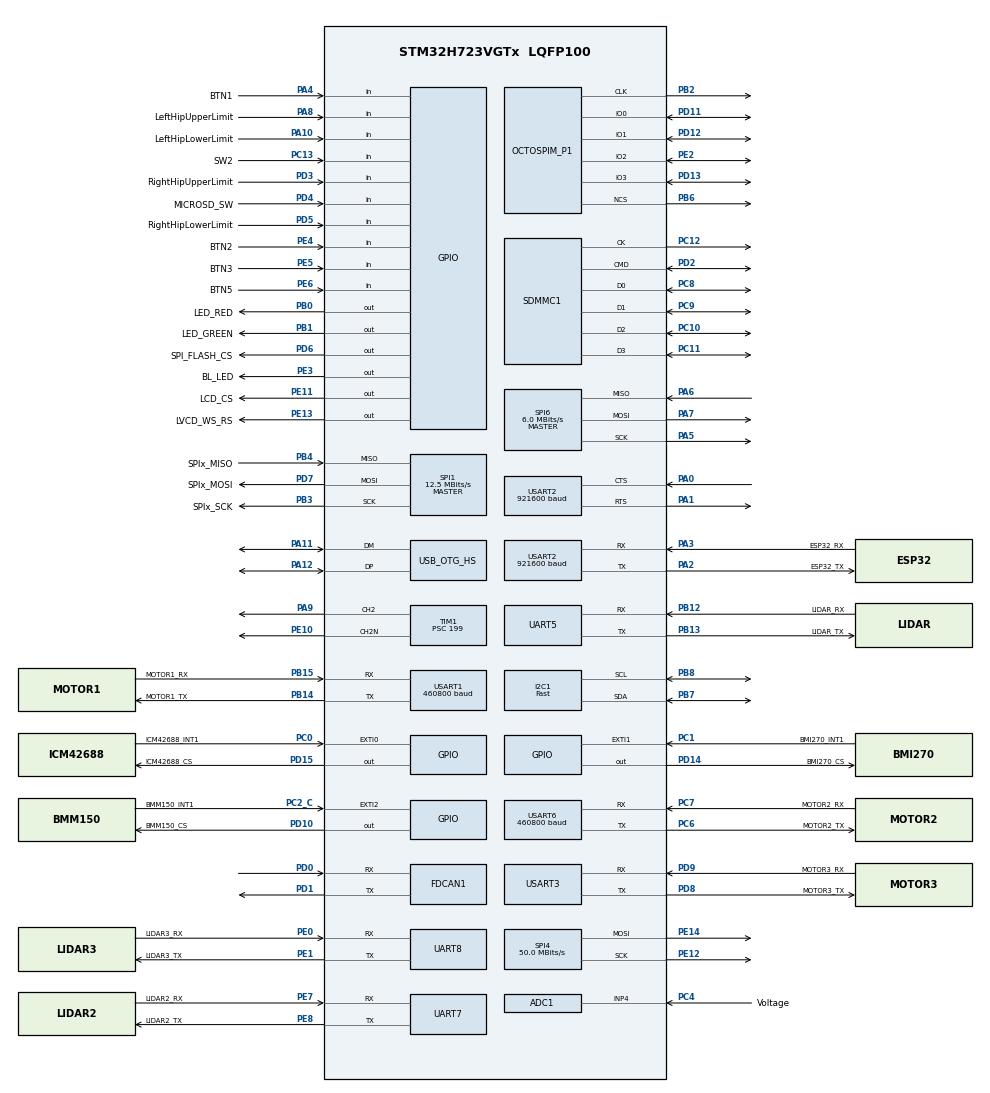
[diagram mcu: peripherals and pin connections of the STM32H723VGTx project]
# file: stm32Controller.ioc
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ADC1.Channel-0\#ChannelRegularConversion=ADC_CHANNEL_4
ADC1.NbrOfConversionFlag=1
ADC1.OffsetNumber-0\#ChannelRegularConversion=ADC_OFFSET_NONE
ADC1.OffsetSignedSaturation-0\#ChannelRegularConversion=DISABLE
ADC1.OversamplingMode=ENABLE
ADC1.Rank-0\#ChannelRegularConversion=1
ADC1.Ratio=16
ADC1.SamplingTime-0\#ChannelRegularConversion=ADC_SAMPLETIME_810CYCLES_5
ADC1.master=1
Bdma.Request0=SPI6_RX
Bdma.Request1=SPI6_TX
Bdma.RequestsNb=2
Bdma.SPI6_RX.0.Direction=DMA_PERIPH_TO_MEMORY
Bdma.SPI6_RX.0.EventEnable=DISABLE
Bdma.SPI6_RX.0.Instance=BDMA_Channel0
Bdma.SPI6_RX.0.MemDataAlignment=DMA_MDATAALIGN_BYTE
Bdma.SPI6_RX.0.MemInc=DMA_MINC_ENABLE
Bdma.SPI6_RX.0.Mode=DMA_NORMAL
Bdma.SPI6_RX.0.PeriphDataAlignment=DMA_PDATAALIGN_BYTE
Bdma.SPI6_RX.0.PeriphInc=DMA_PINC_DISABLE
Bdma.SPI6_RX.0.Polarity=HAL_DMAMUX_REQ_GEN_RISING
Bdma.SPI6_RX.0.Priority=DMA_PRIORITY_HIGH
Bdma.SPI6_RX.0.RequestNumber=1
Bdma.SPI6_RX.0.SignalID=NONE
Bdma.SPI6_RX.0.SyncEnable=DISABLE
Bdma.SPI6_RX.0.SyncPolarity=HAL_DMAMUX_SYNC_NO_EVENT
Bdma.SPI6_RX.0.SyncRequestNumber=1
Bdma.SPI6_RX.0.SyncSignalID=NONE
Bdma.SPI6_TX.1.Direction=DMA_MEMORY_TO_PERIPH
Bdma.SPI6_TX.1.EventEnable=DISABLE
Bdma.SPI6_TX.1.Instance=BDMA_Channel1
Bdma.SPI6_TX.1.MemDataAlignment=DMA_MDATAALIGN_BYTE
Bdma.SPI6_TX.1.MemInc=DMA_MINC_ENABLE
Bdma.SPI6_TX.1.Mode=DMA_NORMAL
Bdma.SPI6_TX.1.PeriphDataAlignment=DMA_PDATAALIGN_BYTE
Bdma.SPI6_TX.1.PeriphInc=DMA_PINC_DISABLE
Bdma.SPI6_TX.1.Polarity=HAL_DMAMUX_REQ_GEN_RISING
Bdma.SPI6_TX.1.Priority=DMA_PRIORITY_HIGH
Bdma.SPI6_TX.1.RequestNumber=1
Bdma.SPI6_TX.1.SignalID=NONE
Bdma.SPI6_TX.1.SyncEnable=DISABLE
Bdma.SPI6_TX.1.SyncPolarity=HAL_DMAMUX_SYNC_NO_EVENT
Bdma.SPI6_TX.1.SyncRequestNumber=1
Bdma.SPI6_TX.1.SyncSignalID=NONE
CORTEX_M7.CPU_DCache=Enabled
CORTEX_M7.CPU_ICache=Enabled
CORTEX_M7.default_mode_Activation=1
Dma.Request0=USART2_RX
Dma.Request1=USART2_TX
Dma.Request2=USART1_RX
Dma.Request3=USART1_TX
Dma.Request4=USART6_RX
Dma.Request5=USART6_TX
Dma.Request6=UART5_RX
Dma.Request7=UART7_RX
Dma.Request8=USART3_RX
Dma.Request9=USART3_TX
Dma.UART5_RX.6.Direction=DMA_PERIPH_TO_MEMORY
Dma.UART5_RX.6.EventEnable=DISABLE
Dma.UART5_RX.6.FIFOMode=DMA_FIFOMODE_DISABLE
Dma.UART5_RX.6.Instance=DMA2_Stream2
Dma.UART5_RX.6.MemDataAlignment=DMA_MDATAALIGN_BYTE
Dma.UART5_RX.6.MemInc=DMA_MINC_ENABLE
Dma.UART5_RX.6.Mode=DMA_CIRCULAR
Dma.UART5_RX.6.PeriphDataAlignment=DMA_PDATAALIGN_BYTE
Dma.UART5_RX.6.PeriphInc=DMA_PINC_DISABLE
Dma.UART5_RX.6.Polarity=HAL_DMAMUX_REQ_GEN_RISING
Dma.UART5_RX.6.Priority=DMA_PRIORITY_MEDIUM
Dma.UART5_RX.6.RequestNumber=1
Dma.UART5_RX.6.SignalID=NONE
Dma.UART5_RX.6.SyncEnable=DISABLE
Dma.UART5_RX.6.SyncPolarity=HAL_DMAMUX_SYNC_NO_EVENT
Dma.UART5_RX.6.SyncRequestNumber=1
Dma.UART5_RX.6.SyncSignalID=NONE
Dma.UART7_RX.7.Direction=DMA_PERIPH_TO_MEMORY
Dma.UART7_RX.7.EventEnable=DISABLE
Dma.UART7_RX.7.FIFOMode=DMA_FIFOMODE_DISABLE
Dma.UART7_RX.7.Instance=DMA2_Stream3
Dma.UART7_RX.7.MemDataAlignment=DMA_MDATAALIGN_BYTE
Dma.UART7_RX.7.MemInc=DMA_MINC_ENABLE
Dma.UART7_RX.7.Mode=DMA_CIRCULAR
Dma.UART7_RX.7.PeriphDataAlignment=DMA_PDATAALIGN_BYTE
Dma.UART7_RX.7.PeriphInc=DMA_PINC_DISABLE
Dma.UART7_RX.7.Polarity=HAL_DMAMUX_REQ_GEN_RISING
Dma.UART7_RX.7.Priority=DMA_PRIORITY_MEDIUM
Dma.UART7_RX.7.RequestNumber=1
Dma.UART7_RX.7.SignalID=NONE
Dma.UART7_RX.7.SyncEnable=DISABLE
Dma.UART7_RX.7.SyncPolarity=HAL_DMAMUX_SYNC_NO_EVENT
Dma.UART7_RX.7.SyncRequestNumber=1
Dma.UART7_RX.7.SyncSignalID=NONE
Dma.USART1_RX.2.Direction=DMA_PERIPH_TO_MEMORY
Dma.USART1_RX.2.EventEnable=DISABLE
Dma.USART1_RX.2.FIFOMode=DMA_FIFOMODE_DISABLE
Dma.USART1_RX.2.Instance=DMA1_Stream6
Dma.USART1_RX.2.MemDataAlignment=DMA_MDATAALIGN_BYTE
Dma.USART1_RX.2.MemInc=DMA_MINC_ENABLE
Dma.USART1_RX.2.Mode=DMA_CIRCULAR
Dma.USART1_RX.2.PeriphDataAlignment=DMA_PDATAALIGN_BYTE
Dma.USART1_RX.2.PeriphInc=DMA_PINC_DISABLE
Dma.USART1_RX.2.Polarity=HAL_DMAMUX_REQ_GEN_RISING
Dma.USART1_RX.2.Priority=DMA_PRIORITY_MEDIUM
Dma.USART1_RX.2.RequestNumber=1
Dma.USART1_RX.2.SignalID=NONE
Dma.USART1_RX.2.SyncEnable=DISABLE
Dma.USART1_RX.2.SyncPolarity=HAL_DMAMUX_SYNC_NO_EVENT
Dma.USART1_RX.2.SyncRequestNumber=1
Dma.USART1_RX.2.SyncSignalID=NONE
Dma.USART1_TX.3.Direction=DMA_MEMORY_TO_PERIPH
Dma.USART1_TX.3.EventEnable=DISABLE
Dma.USART1_TX.3.FIFOMode=DMA_FIFOMODE_DISABLE
Dma.USART1_TX.3.Instance=DMA1_Stream7
Dma.USART1_TX.3.MemDataAlignment=DMA_MDATAALIGN_BYTE
Dma.USART1_TX.3.MemInc=DMA_MINC_ENABLE
Dma.USART1_TX.3.Mode=DMA_NORMAL
Dma.USART1_TX.3.PeriphDataAlignment=DMA_PDATAALIGN_BYTE
Dma.USART1_TX.3.PeriphInc=DMA_PINC_DISABLE
Dma.USART1_TX.3.Polarity=HAL_DMAMUX_REQ_GEN_RISING
Dma.USART1_TX.3.Priority=DMA_PRIORITY_MEDIUM
Dma.USART1_TX.3.RequestNumber=1
Dma.USART1_TX.3.SignalID=NONE
Dma.USART1_TX.3.SyncEnable=DISABLE
Dma.USART1_TX.3.SyncPolarity=HAL_DMAMUX_SYNC_NO_EVENT
Dma.USART1_TX.3.SyncRequestNumber=1
Dma.USART1_TX.3.SyncSignalID=NONE
Dma.USART2_RX.0.Direction=DMA_PERIPH_TO_MEMORY
Dma.USART2_RX.0.EventEnable=DISABLE
Dma.USART2_RX.0.FIFOMode=DMA_FIFOMODE_DISABLE
Dma.USART2_RX.0.Instance=DMA1_Stream4
Dma.USART2_RX.0.MemDataAlignment=DMA_MDATAALIGN_BYTE
Dma.USART2_RX.0.MemInc=DMA_MINC_ENABLE
Dma.USART2_RX.0.Mode=DMA_CIRCULAR
Dma.USART2_RX.0.PeriphDataAlignment=DMA_PDATAALIGN_BYTE
Dma.USART2_RX.0.PeriphInc=DMA_PINC_DISABLE
Dma.USART2_RX.0.Polarity=HAL_DMAMUX_REQ_GEN_RISING
Dma.USART2_RX.0.Priority=DMA_PRIORITY_HIGH
Dma.USART2_RX.0.RequestNumber=1
Dma.USART2_RX.0.SignalID=NONE
Dma.USART2_RX.0.SyncEnable=DISABLE
Dma.USART2_RX.0.SyncPolarity=HAL_DMAMUX_SYNC_NO_EVENT
Dma.USART2_RX.0.SyncRequestNumber=1
Dma.USART2_RX.0.SyncSignalID=NONE
Dma.USART2_TX.1.Direction=DMA_MEMORY_TO_PERIPH
Dma.USART2_TX.1.EventEnable=DISABLE
Dma.USART2_TX.1.FIFOMode=DMA_FIFOMODE_DISABLE
Dma.USART2_TX.1.Instance=DMA1_Stream5
Dma.USART2_TX.1.MemDataAlignment=DMA_MDATAALIGN_BYTE
Dma.USART2_TX.1.MemInc=DMA_MINC_ENABLE
Dma.USART2_TX.1.Mode=DMA_NORMAL
Dma.USART2_TX.1.PeriphDataAlignment=DMA_PDATAALIGN_BYTE
Dma.USART2_TX.1.PeriphInc=DMA_PINC_DISABLE
Dma.USART2_TX.1.Polarity=HAL_DMAMUX_REQ_GEN_RISING
Dma.USART2_TX.1.Priority=DMA_PRIORITY_MEDIUM
Dma.USART2_TX.1.RequestNumber=1
Dma.USART2_TX.1.SignalID=NONE
Dma.USART2_TX.1.SyncEnable=DISABLE
Dma.USART2_TX.1.SyncPolarity=HAL_DMAMUX_SYNC_NO_EVENT
Dma.USART2_TX.1.SyncRequestNumber=1
Dma.USART2_TX.1.SyncSignalID=NONE
Dma.USART3_RX.8.Direction=DMA_PERIPH_TO_MEMORY
Dma.USART3_RX.8.EventEnable=DISABLE
Dma.USART3_RX.8.FIFOMode=DMA_FIFOMODE_DISABLE
Dma.USART3_RX.8.Instance=DMA2_Stream4
Dma.USART3_RX.8.MemDataAlignment=DMA_MDATAALIGN_BYTE
Dma.USART3_RX.8.MemInc=DMA_MINC_ENABLE
Dma.USART3_RX.8.Mode=DMA_CIRCULAR
Dma.USART3_RX.8.PeriphDataAlignment=DMA_PDATAALIGN_BYTE
Dma.USART3_RX.8.PeriphInc=DMA_PINC_DISABLE
Dma.USART3_RX.8.Polarity=HAL_DMAMUX_REQ_GEN_RISING
Dma.USART3_RX.8.Priority=DMA_PRIORITY_MEDIUM
Dma.USART3_RX.8.RequestNumber=1
Dma.USART3_RX.8.SignalID=NONE
Dma.USART3_RX.8.SyncEnable=DISABLE
Dma.USART3_RX.8.SyncPolarity=HAL_DMAMUX_SYNC_NO_EVENT
Dma.USART3_RX.8.SyncRequestNumber=1
Dma.USART3_RX.8.SyncSignalID=NONE
Dma.USART3_TX.9.Direction=DMA_MEMORY_TO_PERIPH
Dma.USART3_TX.9.EventEnable=DISABLE
Dma.USART3_TX.9.FIFOMode=DMA_FIFOMODE_DISABLE
Dma.USART3_TX.9.Instance=DMA2_Stream5
Dma.USART3_TX.9.MemDataAlignment=DMA_MDATAALIGN_BYTE
Dma.USART3_TX.9.MemInc=DMA_MINC_ENABLE
Dma.USART3_TX.9.Mode=DMA_NORMAL
Dma.USART3_TX.9.PeriphDataAlignment=DMA_PDATAALIGN_BYTE
Dma.USART3_TX.9.PeriphInc=DMA_PINC_DISABLE
Dma.USART3_TX.9.Polarity=HAL_DMAMUX_REQ_GEN_RISING
Dma.USART3_TX.9.Priority=DMA_PRIORITY_MEDIUM
Dma.USART3_TX.9.RequestNumber=1
Dma.USART3_TX.9.SignalID=NONE
Dma.USART3_TX.9.SyncEnable=DISABLE
Dma.USART3_TX.9.SyncPolarity=HAL_DMAMUX_SYNC_NO_EVENT
Dma.USART3_TX.9.SyncRequestNumber=1
Dma.USART3_TX.9.SyncSignalID=NONE
Dma.USART6_RX.4.Direction=DMA_PERIPH_TO_MEMORY
Dma.USART6_RX.4.EventEnable=DISABLE
Dma.USART6_RX.4.FIFOMode=DMA_FIFOMODE_DISABLE
Dma.USART6_RX.4.Instance=DMA2_Stream0
Dma.USART6_RX.4.MemDataAlignment=DMA_MDATAALIGN_BYTE
Dma.USART6_RX.4.MemInc=DMA_MINC_ENABLE
Dma.USART6_RX.4.Mode=DMA_CIRCULAR
Dma.USART6_RX.4.PeriphDataAlignment=DMA_PDATAALIGN_BYTE
Dma.USART6_RX.4.PeriphInc=DMA_PINC_DISABLE
Dma.USART6_RX.4.Polarity=HAL_DMAMUX_REQ_GEN_RISING
Dma.USART6_RX.4.Priority=DMA_PRIORITY_MEDIUM
Dma.USART6_RX.4.RequestNumber=1
Dma.USART6_RX.4.SignalID=NONE
Dma.USART6_RX.4.SyncEnable=DISABLE
Dma.USART6_RX.4.SyncPolarity=HAL_DMAMUX_SYNC_NO_EVENT
Dma.USART6_RX.4.SyncRequestNumber=1
Dma.USART6_RX.4.SyncSignalID=NONE
Dma.USART6_TX.5.Direction=DMA_MEMORY_TO_PERIPH
Dma.USART6_TX.5.EventEnable=DISABLE
Dma.USART6_TX.5.FIFOMode=DMA_FIFOMODE_DISABLE
Dma.USART6_TX.5.Instance=DMA2_Stream1
Dma.USART6_TX.5.MemDataAlignment=DMA_MDATAALIGN_BYTE
Dma.USART6_TX.5.MemInc=DMA_MINC_ENABLE
Dma.USART6_TX.5.Mode=DMA_NORMAL
Dma.USART6_TX.5.PeriphDataAlignment=DMA_PDATAALIGN_BYTE
Dma.USART6_TX.5.PeriphInc=DMA_PINC_DISABLE
Dma.USART6_TX.5.Polarity=HAL_DMAMUX_REQ_GEN_RISING
Dma.USART6_TX.5.Priority=DMA_PRIORITY_MEDIUM
Dma.USART6_TX.5.RequestNumber=1
Dma.USART6_TX.5.SignalID=NONE
Dma.USART6_TX.5.SyncEnable=DISABLE
Dma.USART6_TX.5.SyncPolarity=HAL_DMAMUX_SYNC_NO_EVENT
Dma.USART6_TX.5.SyncRequestNumber=1
Dma.USART6_TX.5.SyncSignalID=NONE
FATFS.BSP.number=1
FATFS.USE_DMA_CODE_SD=1
FATFS._FS_EXFAT=1
FATFS._USE_LFN=1
FATFS0.BSP.STBoard=false
FATFS0.BSP.api=Unknown
FATFS0.BSP.instance=PD4
FATFS0.BSP.ip=GPIO
FATFS0.BSP.mode=Input
FATFS0.BSP.name=Detect_SDIO
FATFS0.BSP.solution=PD4
FDCAN1.AutoRetransmission=ENABLE
FDCAN1.CalculateBaudRateNominal=500000
FDCAN1.CalculateTimeBitNominal=2000
FDCAN1.CalculateTimeQuantumNominal=100.0
FDCAN1.NominalPrescaler=10
FDCAN1.NominalTimeSeg1=15
FDCAN1.NominalTimeSeg2=4
FDCAN1.RxFifo0ElmtsNbr=8
FDCAN1.StdFiltersNbr=4
FDCAN1.TxBuffersNbr=16
FDCAN1.TxFifoQueueElmtsNbr=16
I2C1.I2C_Speed_Mode=I2C_Fast
I2C1.Timing=0x009034B6
IWDG1.Prescaler=IWDG_PRESCALER_256
IWDG1.Reload=500
IWDG1.Window=500
Mcu.Family=STM32H7
Mcu.Name=STM32H723VGTx
Mcu.Package=LQFP100
Mdma.MDMA_Channel0.OCTOSPI1_FIFO_TH.0.BlockCount=1
Mdma.MDMA_Channel0.OCTOSPI1_FIFO_TH.0.BlockDataLength=1
Mdma.MDMA_Channel0.OCTOSPI1_FIFO_TH.0.BufferTransferLength=16
Mdma.MDMA_Channel0.OCTOSPI1_FIFO_TH.0.CircularMode=MDMA_LINEAR_LIST
Mdma.MDMA_Channel0.OCTOSPI1_FIFO_TH.0.DataAlignment=MDMA_DATAALIGN_PACKENABLE
Mdma.MDMA_Channel0.OCTOSPI1_FIFO_TH.0.DestBlockAddressOffset=0
Mdma.MDMA_Channel0.OCTOSPI1_FIFO_TH.0.DestBurst=MDMA_DEST_BURST_SINGLE
Mdma.MDMA_Channel0.OCTOSPI1_FIFO_TH.0.DestDataSize=MDMA_DEST_DATASIZE_WORD
Mdma.MDMA_Channel0.OCTOSPI1_FIFO_TH.0.DestinationInc=MDMA_DEST_INC_DISABLE
Mdma.MDMA_Channel0.OCTOSPI1_FIFO_TH.0.DstAddress=0
Mdma.MDMA_Channel0.OCTOSPI1_FIFO_TH.0.Endianness=MDMA_LITTLE_ENDIANNESS_PRESERVE
Mdma.MDMA_Channel0.OCTOSPI1_FIFO_TH.0.Instance=MDMA_Channel0
Mdma.MDMA_Channel0.OCTOSPI1_FIFO_TH.0.MaskAddress=0
Mdma.MDMA_Channel0.OCTOSPI1_FIFO_TH.0.MaskData=0
Mdma.MDMA_Channel0.OCTOSPI1_FIFO_TH.0.Priority=MDMA_PRIORITY_LOW
Mdma.MDMA_Channel0.OCTOSPI1_FIFO_TH.0.Rank=First
Mdma.MDMA_Channel0.OCTOSPI1_FIFO_TH.0.SourceBlockAddressOffset=0
Mdma.MDMA_Channel0.OCTOSPI1_FIFO_TH.0.SourceBurst=MDMA_SOURCE_BURST_SINGLE
Mdma.MDMA_Channel0.OCTOSPI1_FIFO_TH.0.SourceDataSize=MDMA_SRC_DATASIZE_BYTE
Mdma.MDMA_Channel0.OCTOSPI1_FIFO_TH.0.SourceInc=MDMA_SRC_INC_BYTE
Mdma.MDMA_Channel0.OCTOSPI1_FIFO_TH.0.SrcAddress=0
Mdma.MDMA_Channel0.OCTOSPI1_FIFO_TH.0.TransferTriggerMode=MDMA_BUFFER_TRANSFER
Mdma.MDMA_Channel0.Request0=OCTOSPI1_FIFO_TH
Mdma.MDMA_Channel0.RequestsNb=1
Mdma.RequestSet0=MDMA_Channel0
Mdma.RequestSetsNb=1
NVIC.BDMA_Channel0_IRQn=true\:0\:0\:false\:false\:true\:false\:true\:true
NVIC.BDMA_Channel1_IRQn=true\:0\:0\:false\:false\:true\:false\:true\:true
NVIC.DMA1_Stream4_IRQn=true\:0\:0\:false\:false\:true\:false\:true\:true
NVIC.DMA1_Stream5_IRQn=true\:0\:0\:false\:false\:true\:false\:true\:true
NVIC.DMA1_Stream6_IRQn=true\:0\:0\:false\:false\:true\:false\:true\:true
NVIC.DMA1_Stream7_IRQn=true\:0\:0\:false\:false\:true\:false\:true\:true
NVIC.DMA2_Stream0_IRQn=true\:0\:0\:false\:false\:true\:false\:true\:true
NVIC.DMA2_Stream1_IRQn=true\:0\:0\:false\:false\:true\:false\:true\:true
NVIC.DMA2_Stream2_IRQn=true\:0\:0\:false\:false\:true\:false\:true\:true
NVIC.DMA2_Stream3_IRQn=true\:0\:0\:false\:false\:true\:false\:true\:true
NVIC.DMA2_Stream4_IRQn=true\:0\:0\:false\:false\:true\:false\:true\:true
NVIC.DMA2_Stream5_IRQn=true\:0\:0\:false\:false\:true\:false\:true\:true
NVIC.EXTI0_IRQn=true\:0\:0\:false\:false\:true\:true\:true\:true
NVIC.EXTI1_IRQn=true\:0\:0\:false\:false\:true\:true\:true\:true
NVIC.EXTI2_IRQn=true\:0\:0\:false\:false\:true\:true\:true\:true
NVIC.FDCAN1_IT0_IRQn=true\:0\:0\:false\:false\:true\:true\:true\:true
NVIC.I2C1_ER_IRQn=true\:0\:0\:false\:false\:true\:true\:true\:true
NVIC.I2C1_EV_IRQn=true\:0\:0\:false\:false\:true\:true\:true\:true
NVIC.MDMA_IRQn=true\:0\:0\:false\:false\:true\:false\:true\:true
NVIC.OCTOSPI1_IRQn=true\:0\:0\:false\:false\:true\:true\:true\:true
NVIC.OTG_HS_IRQn=true\:0\:0\:false\:false\:true\:false\:true\:true
NVIC.PriorityGroup=NVIC_PRIORITYGROUP_4
NVIC.SDMMC1_IRQn=true\:6\:0\:true\:false\:true\:true\:true\:true
NVIC.SPI6_IRQn=true\:0\:0\:false\:false\:true\:false\:true\:true
NVIC.TIM2_IRQn=true\:5\:0\:true\:false\:true\:true\:true\:true
NVIC.USART1_IRQn=true\:0\:0\:false\:false\:true\:true\:true\:true
NVIC.USART2_IRQn=true\:0\:0\:false\:false\:true\:true\:true\:true
NVIC.USART3_IRQn=true\:0\:0\:false\:false\:true\:true\:true\:true
NVIC.USART6_IRQn=true\:0\:0\:false\:false\:true\:true\:true\:true
OCTOSPI1.ChipSelectHighTime=2
OCTOSPI1.ClockMode=HAL_OSPI_CLOCK_MODE_3
OCTOSPI1.ClockPrescaler=3-1
OCTOSPI1.DeviceSize=23
OCTOSPI1.FifoThreshold=16
OCTOSPI1.MemoryType=HAL_OSPI_MEMTYPE_MICRON
OCTOSPI1.SampleShifting=HAL_OSPI_SAMPLE_SHIFTING_HALFCYCLE
PA0.Mode=CTS_RTS
PA0.Signal=USART2_CTS
PA1.Mode=CTS_RTS
PA1.Signal=USART2_RTS
PA10.GPIO_Label=LeftHipLowerLimit
PA10.GPIO_PuPd=GPIO_PULLUP
PA10.Signal=GPIO_Input
PA11.Mode=Device_Only_FS
PA11.Signal=USB_OTG_HS_DM
PA12.Mode=Device_Only_FS
PA12.Signal=USB_OTG_HS_DP
PA13(JTMS/SWDIO).Mode=Serial_Wire
PA13(JTMS/SWDIO).Signal=DEBUG_JTMS-SWDIO
PA14(JTCK/SWCLK).Mode=Serial_Wire
PA14(JTCK/SWCLK).Signal=DEBUG_JTCK-SWCLK
PA2.GPIO_Label=ESP32_TX
PA2.Mode=Asynchronous
PA2.Signal=USART2_TX
PA3.GPIO_Label=ESP32_RX
PA3.Mode=Asynchronous
PA3.Signal=USART2_RX
PA4.GPIO_Label=BTN1
PA4.Signal=GPIO_Input
PA5.GPIO_Mode=GPIO_MODE_AF_PP
PA5.GPIO_Speed=GPIO_SPEED_FREQ_VERY_HIGH
PA5.Mode=Full_Duplex_Master
PA5.Signal=SPI6_SCK
PA6.GPIO_Speed=GPIO_SPEED_FREQ_VERY_HIGH
PA6.Mode=Full_Duplex_Master
PA6.Signal=SPI6_MISO
PA7.GPIO_Speed=GPIO_SPEED_FREQ_VERY_HIGH
PA7.Mode=Full_Duplex_Master
PA7.Signal=SPI6_MOSI
PA8.GPIO_Label=LeftHipUpperLimit
PA8.GPIO_PuPd=GPIO_PULLUP
PA8.Signal=GPIO_Input
PA9.Signal=S_TIM1_CH2
PB0.GPIO_Label=LED_RED
PB0.Signal=GPIO_Output
PB1.GPIO_Label=LED_GREEN
PB1.Signal=GPIO_Output
PB12.GPIO_Label=LIDAR_RX
PB12.Mode=Asynchronous
PB12.Signal=UART5_RX
PB13.GPIO_Label=LIDAR_TX
PB13.Mode=Asynchronous
PB13.Signal=UART5_TX
PB14.GPIO_Label=MOTOR1_TX
PB14.Mode=Asynchronous
PB14.Signal=USART1_TX
PB15.GPIO_Label=MOTOR1_RX
PB15.Mode=Asynchronous
PB15.Signal=USART1_RX
PB2.Mode=O1_P1_CLK
PB2.Signal=OCTOSPIM_P1_CLK
PB3(JTDO/TRACESWO).GPIO_Label=SPIx_SCK
PB3(JTDO/TRACESWO).Mode=Full_Duplex_Master
PB3(JTDO/TRACESWO).Signal=SPI1_SCK
PB4(NJTRST).GPIO_Label=SPIx_MISO
PB4(NJTRST).Mode=Full_Duplex_Master
PB4(NJTRST).Signal=SPI1_MISO
PB6.Mode=OCTOSPI1_Port1_NCS
PB6.Signal=OCTOSPIM_P1_NCS
PB7.Mode=I2C
PB7.Signal=I2C1_SDA
PB8.Mode=I2C
PB8.Signal=I2C1_SCL
PC0.GPIO_Label=ICM42688_INT1
PC0.GPIO_ModeDefaultEXTI=GPIO_MODE_IT_RISING
PC0.Signal=GPXTI0
PC1.GPIO_Label=BMI270_INT1
PC1.Signal=GPXTI1
PC10.Mode=SD_4_bits_Wide_bus
PC10.Signal=SDMMC1_D2
PC11.Mode=SD_4_bits_Wide_bus
PC11.Signal=SDMMC1_D3
PC12.Mode=SD_4_bits_Wide_bus
PC12.Signal=SDMMC1_CK
PC13.GPIO_Label=SW2
PC13.Signal=GPIO_Input
PC2_C.GPIO_Label=BMM150_INT1
PC2_C.Signal=GPXTI2
PC4.GPIO_Label=Voltage
PC4.Signal=ADCx_INP4
PC6.GPIO_Label=MOTOR2_TX
PC6.Mode=Asynchronous
PC6.Signal=USART6_TX
PC7.GPIO_Label=MOTOR2_RX
PC7.Mode=Asynchronous
PC7.Signal=USART6_RX
PC8.Mode=SD_4_bits_Wide_bus
PC8.Signal=SDMMC1_D0
PC9.Mode=SD_4_bits_Wide_bus
PC9.Signal=SDMMC1_D1
PD0.GPIO_Speed=GPIO_SPEED_FREQ_VERY_HIGH
PD0.Mode=FDCAN_Activate
PD0.Signal=FDCAN1_RX
PD1.GPIO_Speed=GPIO_SPEED_FREQ_VERY_HIGH
PD1.Mode=FDCAN_Activate
PD1.Signal=FDCAN1_TX
PD10.GPIO_Label=BMM150_CS
PD10.GPIO_Speed=GPIO_SPEED_FREQ_VERY_HIGH
PD10.PinState=GPIO_PIN_SET
PD10.Signal=GPIO_Output
PD11.Mode=OCTOSPI1_IOL_Port1L
PD11.Signal=OCTOSPIM_P1_IO0
PD12.Mode=OCTOSPI1_IOL_Port1L
PD12.Signal=OCTOSPIM_P1_IO1
PD13.Mode=OCTOSPI1_IOL_Port1L
PD13.Signal=OCTOSPIM_P1_IO3
PD14.GPIO_Label=BMI270_CS
PD14.GPIO_Speed=GPIO_SPEED_FREQ_VERY_HIGH
PD14.PinState=GPIO_PIN_SET
PD14.Signal=GPIO_Output
PD15.GPIO_Label=ICM42688_CS
PD15.GPIO_Speed=GPIO_SPEED_FREQ_VERY_HIGH
PD15.PinState=GPIO_PIN_SET
PD15.Signal=GPIO_Output
PD2.Mode=SD_4_bits_Wide_bus
PD2.Signal=SDMMC1_CMD
PD3.GPIO_Label=RightHipUpperLimit
PD3.GPIO_PuPd=GPIO_PULLUP
PD3.Signal=GPIO_Input
PD4.GPIO_Label=MICROSD_SW
PD4.GPIO_PuPd=GPIO_PULLUP
PD4.Signal=GPIO_Input
PD5.GPIO_Label=RightHipLowerLimit
PD5.GPIO_PuPd=GPIO_PULLUP
PD5.Signal=GPIO_Input
PD6.GPIO_Label=SPI_FLASH_CS
PD6.GPIO_Speed=GPIO_SPEED_FREQ_VERY_HIGH
PD6.PinState=GPIO_PIN_SET
PD6.Signal=GPIO_Output
PD7.GPIO_Label=SPIx_MOSI
PD7.Mode=Full_Duplex_Master
PD7.Signal=SPI1_MOSI
PD8.GPIO_Label=MOTOR3_TX
PD8.Mode=Asynchronous
PD8.Signal=USART3_TX
PD9.GPIO_Label=MOTOR3_RX
PD9.Mode=Asynchronous
PD9.Signal=USART3_RX
PE0.GPIO_Label=LIDAR3_RX
PE0.Mode=Asynchronous
PE0.Signal=UART8_RX
PE1.GPIO_Label=LIDAR3_TX
PE1.Mode=Asynchronous
PE1.Signal=UART8_TX
PE10.Mode=PWM Generation2 CH2 CH2N
PE10.Signal=TIM1_CH2N
PE11.GPIO_Label=LCD_CS
PE11.GPIO_Speed=GPIO_SPEED_FREQ_HIGH
PE11.Signal=GPIO_Output
PE12.Mode=TX_Only_Simplex_Unidirect_Master
PE12.Signal=SPI4_SCK
PE13.GPIO_Label=LVCD_WS_RS
PE13.GPIO_Speed=GPIO_SPEED_FREQ_HIGH
PE13.Signal=GPIO_Output
PE14.Mode=TX_Only_Simplex_Unidirect_Master
PE14.Signal=SPI4_MOSI
PE2.Mode=OCTOSPI1_IOL_Port1L
PE2.Signal=OCTOSPIM_P1_IO2
PE3.GPIO_Label=BL_LED
PE3.Signal=GPIO_Output
PE4.GPIO_Label=BTN2
PE4.GPIO_PuPd=GPIO_PULLUP
PE4.Signal=GPIO_Input
PE5.GPIO_Label=BTN3
PE5.GPIO_PuPd=GPIO_PULLUP
PE5.Signal=GPIO_Input
PE6.GPIO_Label=BTN5
PE6.GPIO_PuPd=GPIO_PULLUP
PE6.Signal=GPIO_Input
PE7.GPIO_Label=LIDAR2_RX
PE7.Mode=Asynchronous
PE7.Signal=UART7_RX
PE8.GPIO_Label=LIDAR2_TX
PE8.Mode=Asynchronous
PE8.Signal=UART7_TX
PH0-OSC_IN.Mode=HSE-External-Oscillator
PH0-OSC_IN.Signal=RCC_OSC_IN
PH1-OSC_OUT.Mode=HSE-External-Oscillator
PH1-OSC_OUT.Signal=RCC_OSC_OUT
ProjectManager.HeapSize=0x200
ProjectManager.StackSize=0x400
ProjectManager.TargetToolchain=CMake
RCC.ADCFreq_Value=100000000
RCC.APB1Freq_Value=100000000
RCC.APB2Freq_Value=100000000
RCC.APB3Freq_Value=100000000
RCC.APB4Freq_Value=100000000
RCC.CortexFreq_Value=400000000
RCC.D1PPRE=RCC_APB3_DIV2
RCC.D2PPRE1=RCC_APB1_DIV2
RCC.D2PPRE2=RCC_APB2_DIV2
RCC.D3PPRE=RCC_APB4_DIV2
RCC.DIVM1=5
RCC.DIVM2=5
RCC.DIVM3=5
RCC.DIVN1=160
RCC.DIVN2=80
RCC.DIVN3=96
RCC.DIVP2=4
RCC.DIVQ2=4
RCC.DIVQ3=10
RCC.DIVR2=4
RCC.FDCANCLockSelection=RCC_FDCANCLKSOURCE_PLL2
RCC.HCLKFreq_Value=200000000
RCC.HPRE=RCC_HCLK_DIV2
RCC.HSE_VALUE=25000000
RCC.PLL2FRACN=0
RCC.PLL3FRACN=0
RCC.PLLFRACN=0
RCC.PLLSourceVirtual=RCC_PLLSOURCE_HSE
RCC.QSPICLockSelection=RCC_OSPICLKSOURCE_PLL2
RCC.SDMMC1CLockSelection=RCC_SDMMCCLKSOURCE_PLL2
RCC.SPI123CLockSelection=RCC_SPI123CLKSOURCE_PLL2
RCC.SPI6CLockSelection=RCC_SPI6CLKSOURCE_PLL3
RCC.SYSCLKFreq_VALUE=400000000
RCC.SYSCLKSource=RCC_SYSCLKSOURCE_PLLCLK
RCC.USBCLockSelection=RCC_USBCLKSOURCE_PLL3
RCC.USBFreq_Value=48000000
SDMMC1.ClockDiv=1
SH.ADCx_INP4.0=ADC1_INP4,IN4-Single-Ended
SH.S_TIM1_CH2.0=TIM1_CH2,PWM Generation2 CH2 CH2N
SPI1.BaudRatePrescaler=SPI_BAUDRATEPRESCALER_8
SPI1.CalculateBaudRate=12.5 MBits/s
SPI1.Direction=SPI_DIRECTION_2LINES
SPI1.Mode=SPI_MODE_MASTER
SPI1.VirtualType=VM_MASTER
SPI4.CalculateBaudRate=50.0 MBits/s
SPI4.Direction=SPI_DIRECTION_2LINES_TXONLY
SPI4.Mode=SPI_MODE_MASTER
SPI4.VirtualType=VM_MASTER
SPI6.BaudRatePrescaler=SPI_BAUDRATEPRESCALER_8
SPI6.CLKPolarity=SPI_POLARITY_LOW
SPI6.CalculateBaudRate=6.0 MBits/s
SPI6.DataSize=SPI_DATASIZE_8BIT
SPI6.Direction=SPI_DIRECTION_2LINES
SPI6.Mode=SPI_MODE_MASTER
SPI6.VirtualType=VM_MASTER
TIM1.AutoReloadPreload=TIM_AUTORELOAD_PRELOAD_ENABLE
TIM1.Channel-PWM\ Generation2\ CH2\ CH2N=TIM_CHANNEL_2
TIM1.Period=44
TIM1.Prescaler=199
TIM2.AutoReloadPreload=TIM_AUTORELOAD_PRELOAD_ENABLE
TIM2.Period=999
TIM2.Prescaler=499
USART1.BaudRate=460800
USART1.VirtualMode-Asynchronous=VM_ASYNC
USART2.BaudRate=921600
USART2.VirtualMode-Asynchronous=VM_ASYNC
USART3.VirtualMode-Asynchronous=VM_ASYNC
USART6.BaudRate=460800
USART6.VirtualMode=VM_ASYNC
USB_DEVICE.CLASS_NAME_HS=CDC
USB_DEVICE.VirtualMode=Cdc
USB_DEVICE.VirtualModeHS=Cdc_HS
USB_OTG_HS.VirtualMode-Device_Only_FS=Device_Only_FS
VP_CRC_VS_CRC.Mode=CRC_Activate
VP_FATFS_VS_SDIO.Mode=SDIO
VP_IWDG1_VS_IWDG.Mode=IWDG_Activate
VP_MEMORYMAP_VS_MEMORYMAP.Mode=CurAppReg
VP_OCTOSPI1_VS_quad.Mode=quad_mode
VP_TIM2_VS_ClockSourceINT.Mode=Internal
VP_USB_DEVICE_VS_USB_DEVICE_CDC_HS.Mode=CDC_HS
board=custom

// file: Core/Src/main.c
/* USER CODE BEGIN Header */
/**
 ******************************************************************************
 * @file           : main.c
 * @brief          : Main program body
 ******************************************************************************
 * @attention
 *
 * Copyright (c) 2025 STMicroelectronics.
 * All rights reserved.
 *
 * This software is licensed under terms that can be found in the LICENSE file
 * in the root directory of this software component.
 * If no LICENSE file comes with this software, it is provided AS-IS.
 *
 ******************************************************************************
 */
/* USER CODE END Header */
#include "main.h"
#include "fatfs.h"
#include "usb_device.h"

/* USER CODE BEGIN Includes */
#include "app_main.h"
#include "bsp_driver_sd.h"
#include "debug_wdog.h"
#include "log.h"
#include "app_config.h"
#include "system_reboot.h"
#include "param_storage.h"
/* USER CODE END Includes */

ADC_HandleTypeDef hadc1;

CRC_HandleTypeDef hcrc;

FDCAN_HandleTypeDef hfdcan1;

I2C_HandleTypeDef hi2c1;

IWDG_HandleTypeDef hiwdg1;

OSPI_HandleTypeDef hospi1;
MDMA_HandleTypeDef hmdma_octospi1_fifo_th;

SD_HandleTypeDef hsd1;

SPI_HandleTypeDef hspi1;
SPI_HandleTypeDef hspi4;
SPI_HandleTypeDef hspi6;
DMA_HandleTypeDef hdma_spi6_rx;
DMA_HandleTypeDef hdma_spi6_tx;

TIM_HandleTypeDef htim1;
TIM_HandleTypeDef htim2;

UART_HandleTypeDef huart5;
UART_HandleTypeDef huart7;
UART_HandleTypeDef huart8;
UART_HandleTypeDef huart1;
UART_HandleTypeDef huart2;
UART_HandleTypeDef huart3;
UART_HandleTypeDef huart6;
DMA_HandleTypeDef hdma_uart5_rx;
DMA_HandleTypeDef hdma_uart7_rx;
DMA_HandleTypeDef hdma_usart1_rx;
DMA_HandleTypeDef hdma_usart1_tx;
DMA_HandleTypeDef hdma_usart2_rx;
DMA_HandleTypeDef hdma_usart2_tx;
DMA_HandleTypeDef hdma_usart3_rx;
DMA_HandleTypeDef hdma_usart3_tx;
DMA_HandleTypeDef hdma_usart6_rx;
DMA_HandleTypeDef hdma_usart6_tx;

void SystemClock_Config(void);
void PeriphCommonClock_Config(void);
static void MPU_Config(void);
static void MX_GPIO_Init(void);
static void MX_DMA_Init(void);
static void MX_BDMA_Init(void);
static void MX_MDMA_Init(void);
static void MX_I2C1_Init(void);
static void MX_OCTOSPI1_Init(void);
static void MX_SDMMC1_SD_Init(void);
static void MX_USART2_UART_Init(void);
static void MX_USART1_UART_Init(void);
static void MX_USART6_UART_Init(void);
static void MX_SPI1_Init(void);
static void MX_SPI4_Init(void);
static void MX_TIM1_Init(void);
static void MX_UART5_Init(void);
static void MX_UART7_Init(void);
static void MX_UART8_Init(void);
static void MX_USART3_UART_Init(void);
static void MX_SPI6_Init(void);
static void MX_CRC_Init(void);
static void MX_IWDG1_Init(void);
static void MX_ADC1_Init(void);
static void MX_TIM2_Init(void);
static void MX_FDCAN1_Init(void);

int main(void)
{

  /* MPU Configuration--------------------------------------------------------*/
  MPU_Config();

  /* Enable the CPU Cache */

  /* Enable I-Cache---------------------------------------------------------*/
  SCB_EnableICache();

  /* Enable D-Cache---------------------------------------------------------*/
  SCB_EnableDCache();

  /* MCU Configuration--------------------------------------------------------*/

  /* Reset of all peripherals, Initializes the Flash interface and the Systick. */
  HAL_Init();

  /* USER CODE BEGIN Init */
  /*
   * Initialize debug watchdog early to detect IWDG resets.
   * Must be after HAL_Init() for backup SRAM access.
   * NOTE: WDOG_CHECKPOINT() cannot be called yet - IWDG not initialized.
   */
  debug_wdog_init();
#if DEBUG_FAULTS
  /* Make bus faults precise and trap on bus errors during debug. */
  SCB->SHCSR |= SCB_SHCSR_BUSFAULTENA_Msk;
#if defined(SCnSCB_ACTLR_DISDEFWBUF_Msk)
  SCnSCB->ACTLR |= SCnSCB_ACTLR_DISDEFWBUF_Msk;
#endif
#endif
  /* USER CODE END Init */

  /* Configure the system clock */
  SystemClock_Config();

  /* Configure the peripherals common clocks */
  PeriphCommonClock_Config();

  /* USER CODE BEGIN SysInit */
  /* NOTE: WDOG_CHECKPOINT() cannot be called yet - IWDG not initialized */
  /* USER CODE END SysInit */

  /* Initialize all configured peripherals */
  MX_GPIO_Init();
  MX_DMA_Init();
  MX_BDMA_Init();
  MX_MDMA_Init();
  MX_I2C1_Init();
  MX_OCTOSPI1_Init();
  MX_SDMMC1_SD_Init();
  MX_USB_DEVICE_Init();
  MX_USART2_UART_Init();
  MX_FATFS_Init();
  MX_USART1_UART_Init();
  MX_USART6_UART_Init();
  MX_SPI1_Init();
  MX_SPI4_Init();
  MX_TIM1_Init();
  MX_UART5_Init();
  MX_UART7_Init();
  MX_UART8_Init();
  MX_USART3_UART_Init();
  MX_SPI6_Init();
  MX_CRC_Init();
  MX_IWDG1_Init();
  MX_ADC1_Init();
  MX_TIM2_Init();
  MX_FDCAN1_Init();
  /* USER CODE BEGIN 2 */
  WDOG_CHECKPOINT(WDOG_CP_IWDG_INIT);

  /*
   * Log watchdog reset info if this was a recovery from hang.
   * Note: USB not yet enumerated, so this goes to the ring buffer
   * and will be sent once USB is ready.
   */
  if (debug_wdog_was_reset()) {
    app_log_printf("[WDOG] Reset detected! Last checkpoint: 0x%04X (%s)\r\n",
                   debug_wdog_get_last_checkpoint(),
                   debug_wdog_checkpoint_name(debug_wdog_get_last_checkpoint()));
  }
  debug_wdog_fault_t fault;
  if (debug_wdog_get_fault(&fault)) {
    app_log_printf("[FAULT] hfsr=0x%08lX cfsr=0x%08lX bfar=0x%08lX "
                   "mmfar=0x%08lX lr=0x%08lX pc=0x%08lX psr=0x%08lX sp=0x%08lX\r\n",
                   (unsigned long)fault.hfsr,
                   (unsigned long)fault.cfsr,
                   (unsigned long)fault.bfar,
                   (unsigned long)fault.mmfar,
                   (unsigned long)fault.lr,
                   (unsigned long)fault.pc,
                   (unsigned long)fault.psr,
                   (unsigned long)fault.sp);
    uint8_t fault_in_param = 0U;
    if (fault.bfar >= PARAM_FLASH_BASE && fault.bfar < PARAM_FLASH_END) {
      fault_in_param = 1U;
    }
    if (fault.mmfar >= PARAM_FLASH_BASE && fault.mmfar < PARAM_FLASH_END) {
      fault_in_param = 1U;
    }
    if (fault_in_param != 0U && (fault.cfsr & 0x0000FF00U) != 0U) {
      app_log_printf("[WDOG] Param flash fault; erasing param sector\r\n");
      int erase_rc = param_storage_erase();
      if (erase_rc == PARAM_OK) {
        app_log_printf("[WDOG] Param flash erase OK\r\n");
      } else {
        app_log_printf("[WDOG] Param flash erase FAILED (%d)\r\n", erase_rc);
      }
      app_log_flush_blocking(50U);
    }
  }

  /*
   * EXTI Race Condition Fix:
   * CubeMX enables IMU EXTI interrupts in MX_GPIO_Init(), but IMU sensors
   * are not initialized until app_init(). On cold boot, sensors may be in
   * an undefined state and generate spurious interrupts that corrupt the
   * scheduler state before it's ready.
   *
   * Solution: Disable IMU EXTI immediately after MX_GPIO_Init() completes.
   * They will be re-enabled in app_init() after successful sensor init.
   * See: docs/CodeReview311225.md for full analysis.
   */
  HAL_NVIC_DisableIRQ(ICM42688_INT1_EXTI_IRQn);
  HAL_NVIC_DisableIRQ(BMI270_INT1_EXTI_IRQn);
  HAL_NVIC_DisableIRQ(BMM150_INT1_EXTI_IRQn);
  WDOG_CHECKPOINT(WDOG_CP_EXTI_DISABLE);

  HAL_GPIO_WritePin(LED_GREEN_GPIO_Port, LED_GREEN_Pin, GPIO_PIN_SET);
  WDOG_CHECKPOINT(WDOG_CP_APP_MAIN_ENTER);
  app_main();
  /* USER CODE END 2 */

  /* Infinite loop */
  while (1) {

  }
}

void SystemClock_Config(void)
{
  RCC_OscInitTypeDef RCC_OscInitStruct = {0};
  RCC_ClkInitTypeDef RCC_ClkInitStruct = {0};

  /** Supply configuration update enable
  */
  HAL_PWREx_ConfigSupply(PWR_LDO_SUPPLY);

  /** Configure the main internal regulator output voltage
  */
  __HAL_PWR_VOLTAGESCALING_CONFIG(PWR_REGULATOR_VOLTAGE_SCALE1);

  while(!__HAL_PWR_GET_FLAG(PWR_FLAG_VOSRDY)) {}

  /** Initializes the RCC Oscillators according to the specified parameters
  * in the RCC_OscInitTypeDef structure.
  */
  RCC_OscInitStruct.OscillatorType = RCC_OSCILLATORTYPE_LSI|RCC_OSCILLATORTYPE_HSE;
  RCC_OscInitStruct.HSEState = RCC_HSE_ON;
  RCC_OscInitStruct.LSIState = RCC_LSI_ON;
  RCC_OscInitStruct.PLL.PLLState = RCC_PLL_ON;
  RCC_OscInitStruct.PLL.PLLSource = RCC_PLLSOURCE_HSE;
  RCC_OscInitStruct.PLL.PLLM = 5;
  RCC_OscInitStruct.PLL.PLLN = 160;
  RCC_OscInitStruct.PLL.PLLP = 2;
  RCC_OscInitStruct.PLL.PLLQ = 2;
  RCC_OscInitStruct.PLL.PLLR = 2;
  RCC_OscInitStruct.PLL.PLLRGE = RCC_PLL1VCIRANGE_2;
  RCC_OscInitStruct.PLL.PLLVCOSEL = RCC_PLL1VCOWIDE;
  RCC_OscInitStruct.PLL.PLLFRACN = 0;
  if (HAL_RCC_OscConfig(&RCC_OscInitStruct) != HAL_OK)
  {
    Error_Handler();
  }

  /** Initializes the CPU, AHB and APB buses clocks
  */
  RCC_ClkInitStruct.ClockType = RCC_CLOCKTYPE_HCLK|RCC_CLOCKTYPE_SYSCLK
                              |RCC_CLOCKTYPE_PCLK1|RCC_CLOCKTYPE_PCLK2
                              |RCC_CLOCKTYPE_D3PCLK1|RCC_CLOCKTYPE_D1PCLK1;
  RCC_ClkInitStruct.SYSCLKSource = RCC_SYSCLKSOURCE_PLLCLK;
  RCC_ClkInitStruct.SYSCLKDivider = RCC_SYSCLK_DIV1;
  RCC_ClkInitStruct.AHBCLKDivider = RCC_HCLK_DIV2;
  RCC_ClkInitStruct.APB3CLKDivider = RCC_APB3_DIV2;
  RCC_ClkInitStruct.APB1CLKDivider = RCC_APB1_DIV2;
  RCC_ClkInitStruct.APB2CLKDivider = RCC_APB2_DIV2;
  RCC_ClkInitStruct.APB4CLKDivider = RCC_APB4_DIV2;

  if (HAL_RCC_ClockConfig(&RCC_ClkInitStruct, FLASH_LATENCY_2) != HAL_OK)
  {
    Error_Handler();
  }
}

void PeriphCommonClock_Config(void)
{
  RCC_PeriphCLKInitTypeDef PeriphClkInitStruct = {0};

  /** Initializes the peripherals clock
  */
  PeriphClkInitStruct.PeriphClockSelection = RCC_PERIPHCLK_OSPI|RCC_PERIPHCLK_USB
                              |RCC_PERIPHCLK_SPI6|RCC_PERIPHCLK_ADC
                              |RCC_PERIPHCLK_SDMMC|RCC_PERIPHCLK_SPI1
                              |RCC_PERIPHCLK_FDCAN;
  PeriphClkInitStruct.PLL2.PLL2M = 5;
  PeriphClkInitStruct.PLL2.PLL2N = 80;
  PeriphClkInitStruct.PLL2.PLL2P = 4;
  PeriphClkInitStruct.PLL2.PLL2Q = 4;
  PeriphClkInitStruct.PLL2.PLL2R = 4;
  PeriphClkInitStruct.PLL2.PLL2RGE = RCC_PLL2VCIRANGE_2;
  PeriphClkInitStruct.PLL2.PLL2VCOSEL = RCC_PLL2VCOWIDE;
  PeriphClkInitStruct.PLL2.PLL2FRACN = 0;
  PeriphClkInitStruct.PLL3.PLL3M = 5;
  PeriphClkInitStruct.PLL3.PLL3N = 96;
  PeriphClkInitStruct.PLL3.PLL3P = 2;
  PeriphClkInitStruct.PLL3.PLL3Q = 10;
  PeriphClkInitStruct.PLL3.PLL3R = 2;
  PeriphClkInitStruct.PLL3.PLL3RGE = RCC_PLL3VCIRANGE_2;
  PeriphClkInitStruct.PLL3.PLL3VCOSEL = RCC_PLL3VCOWIDE;
  PeriphClkInitStruct.PLL3.PLL3FRACN = 0;
  PeriphClkInitStruct.OspiClockSelection = RCC_OSPICLKSOURCE_PLL2;
  PeriphClkInitStruct.SdmmcClockSelection = RCC_SDMMCCLKSOURCE_PLL2;
  PeriphClkInitStruct.Spi123ClockSelection = RCC_SPI123CLKSOURCE_PLL2;
  PeriphClkInitStruct.FdcanClockSelection = RCC_FDCANCLKSOURCE_PLL2;
  PeriphClkInitStruct.UsbClockSelection = RCC_USBCLKSOURCE_PLL3;
  PeriphClkInitStruct.AdcClockSelection = RCC_ADCCLKSOURCE_PLL2;
  PeriphClkInitStruct.Spi6ClockSelection = RCC_SPI6CLKSOURCE_PLL3;
  if (HAL_RCCEx_PeriphCLKConfig(&PeriphClkInitStruct) != HAL_OK)
  {
    Error_Handler();
  }
}

static void MX_ADC1_Init(void)
{

  ADC_MultiModeTypeDef multimode = {0};
  ADC_ChannelConfTypeDef sConfig = {0};

  /** Common config
  */
  hadc1.Instance = ADC1;
  hadc1.Init.ClockPrescaler = ADC_CLOCK_ASYNC_DIV1;
  hadc1.Init.Resolution = ADC_RESOLUTION_16B;
  hadc1.Init.ScanConvMode = ADC_SCAN_DISABLE;
  hadc1.Init.EOCSelection = ADC_EOC_SINGLE_CONV;
  hadc1.Init.LowPowerAutoWait = DISABLE;
  hadc1.Init.ContinuousConvMode = DISABLE;
  hadc1.Init.NbrOfConversion = 1;
  hadc1.Init.DiscontinuousConvMode = DISABLE;
  hadc1.Init.ExternalTrigConv = ADC_SOFTWARE_START;
  hadc1.Init.ExternalTrigConvEdge = ADC_EXTERNALTRIGCONVEDGE_NONE;
  hadc1.Init.ConversionDataManagement = ADC_CONVERSIONDATA_DR;
  hadc1.Init.Overrun = ADC_OVR_DATA_PRESERVED;
  hadc1.Init.LeftBitShift = ADC_LEFTBITSHIFT_NONE;
  hadc1.Init.OversamplingMode = ENABLE;
  hadc1.Init.Oversampling.Ratio = 16;
  hadc1.Init.Oversampling.RightBitShift = ADC_RIGHTBITSHIFT_NONE;
  hadc1.Init.Oversampling.TriggeredMode = ADC_TRIGGEREDMODE_SINGLE_TRIGGER;
  hadc1.Init.Oversampling.OversamplingStopReset = ADC_REGOVERSAMPLING_CONTINUED_MODE;
  if (HAL_ADC_Init(&hadc1) != HAL_OK)
  {
    Error_Handler();
  }

  /** Configure the ADC multi-mode
  */
  multimode.Mode = ADC_MODE_INDEPENDENT;
  if (HAL_ADCEx_MultiModeConfigChannel(&hadc1, &multimode) != HAL_OK)
  {
    Error_Handler();
  }

  /** Configure Regular Channel
  */
  sConfig.Channel = ADC_CHANNEL_4;
  sConfig.Rank = ADC_REGULAR_RANK_1;
  sConfig.SamplingTime = ADC_SAMPLETIME_810CYCLES_5;
  sConfig.SingleDiff = ADC_SINGLE_ENDED;
  sConfig.OffsetNumber = ADC_OFFSET_NONE;
  sConfig.Offset = 0;
  sConfig.OffsetSignedSaturation = DISABLE;
  if (HAL_ADC_ConfigChannel(&hadc1, &sConfig) != HAL_OK)
  {
    Error_Handler();
  }

}

static void MX_CRC_Init(void)
{

  hcrc.Instance = CRC;
  hcrc.Init.DefaultPolynomialUse = DEFAULT_POLYNOMIAL_ENABLE;
  hcrc.Init.DefaultInitValueUse = DEFAULT_INIT_VALUE_ENABLE;
  hcrc.Init.InputDataInversionMode = CRC_INPUTDATA_INVERSION_NONE;
  hcrc.Init.OutputDataInversionMode = CRC_OUTPUTDATA_INVERSION_DISABLE;
  hcrc.InputDataFormat = CRC_INPUTDATA_FORMAT_BYTES;
  if (HAL_CRC_Init(&hcrc) != HAL_OK)
  {
    Error_Handler();
  }

}

static void MX_FDCAN1_Init(void)
{

  hfdcan1.Instance = FDCAN1;
  hfdcan1.Init.FrameFormat = FDCAN_FRAME_CLASSIC;
  hfdcan1.Init.Mode = FDCAN_MODE_NORMAL;
  hfdcan1.Init.AutoRetransmission = ENABLE;
  hfdcan1.Init.TransmitPause = DISABLE;
  hfdcan1.Init.ProtocolException = DISABLE;
  hfdcan1.Init.NominalPrescaler = 10;
  hfdcan1.Init.NominalSyncJumpWidth = 1;
  hfdcan1.Init.NominalTimeSeg1 = 15;
  hfdcan1.Init.NominalTimeSeg2 = 4;
  hfdcan1.Init.DataPrescaler = 1;
  hfdcan1.Init.DataSyncJumpWidth = 1;
  hfdcan1.Init.DataTimeSeg1 = 1;
  hfdcan1.Init.DataTimeSeg2 = 1;
  hfdcan1.Init.MessageRAMOffset = 0;
  hfdcan1.Init.StdFiltersNbr = 4;
  hfdcan1.Init.ExtFiltersNbr = 0;
  hfdcan1.Init.RxFifo0ElmtsNbr = 8;
  hfdcan1.Init.RxFifo0ElmtSize = FDCAN_DATA_BYTES_8;
  hfdcan1.Init.RxFifo1ElmtsNbr = 0;
  hfdcan1.Init.RxFifo1ElmtSize = FDCAN_DATA_BYTES_8;
  hfdcan1.Init.RxBuffersNbr = 0;
  hfdcan1.Init.RxBufferSize = FDCAN_DATA_BYTES_8;
  hfdcan1.Init.TxEventsNbr = 0;
  hfdcan1.Init.TxBuffersNbr = 16;
  hfdcan1.Init.TxFifoQueueElmtsNbr = 16;
  hfdcan1.Init.TxFifoQueueMode = FDCAN_TX_FIFO_OPERATION;
  hfdcan1.Init.TxElmtSize = FDCAN_DATA_BYTES_8;
  if (HAL_FDCAN_Init(&hfdcan1) != HAL_OK)
  {
    Error_Handler();
  }

}

static void MX_I2C1_Init(void)
{

  hi2c1.Instance = I2C1;
  hi2c1.Init.Timing = 0x009034B6;
  hi2c1.Init.OwnAddress1 = 0;
  hi2c1.Init.AddressingMode = I2C_ADDRESSINGMODE_7BIT;
  hi2c1.Init.DualAddressMode = I2C_DUALADDRESS_DISABLE;
  hi2c1.Init.OwnAddress2 = 0;
  hi2c1.Init.OwnAddress2Masks = I2C_OA2_NOMASK;
  hi2c1.Init.GeneralCallMode = I2C_GENERALCALL_DISABLE;
  hi2c1.Init.NoStretchMode = I2C_NOSTRETCH_DISABLE;
  if (HAL_I2C_Init(&hi2c1) != HAL_OK)
  {
    Error_Handler();
  }

  /** Configure Analogue filter
  */
  if (HAL_I2CEx_ConfigAnalogFilter(&hi2c1, I2C_ANALOGFILTER_ENABLE) != HAL_OK)
  {
    Error_Handler();
  }

  /** Configure Digital filter
  */
  if (HAL_I2CEx_ConfigDigitalFilter(&hi2c1, 0) != HAL_OK)
  {
    Error_Handler();
  }

}

static void MX_IWDG1_Init(void)
{

  hiwdg1.Instance = IWDG1;
  hiwdg1.Init.Prescaler = IWDG_PRESCALER_256;
  hiwdg1.Init.Window = 500;
  hiwdg1.Init.Reload = 500;
  if (HAL_IWDG_Init(&hiwdg1) != HAL_OK)
  {
    Error_Handler();
  }

}

static void MX_OCTOSPI1_Init(void)
{

  OSPIM_CfgTypeDef sOspiManagerCfg = {0};

  /* OCTOSPI1 parameter configuration*/
  hospi1.Instance = OCTOSPI1;
  hospi1.Init.FifoThreshold = 16;
  hospi1.Init.DualQuad = HAL_OSPI_DUALQUAD_DISABLE;
  hospi1.Init.MemoryType = HAL_OSPI_MEMTYPE_MICRON;
  hospi1.Init.DeviceSize = 23;
  hospi1.Init.ChipSelectHighTime = 2;
  hospi1.Init.FreeRunningClock = HAL_OSPI_FREERUNCLK_DISABLE;
  hospi1.Init.ClockMode = HAL_OSPI_CLOCK_MODE_3;
  hospi1.Init.WrapSize = HAL_OSPI_WRAP_NOT_SUPPORTED;
  hospi1.Init.ClockPrescaler = 3-1;
  hospi1.Init.SampleShifting = HAL_OSPI_SAMPLE_SHIFTING_HALFCYCLE;
  hospi1.Init.DelayHoldQuarterCycle = HAL_OSPI_DHQC_DISABLE;
  hospi1.Init.ChipSelectBoundary = 0;
  hospi1.Init.DelayBlockBypass = HAL_OSPI_DELAY_BLOCK_BYPASSED;
  hospi1.Init.MaxTran = 0;
  hospi1.Init.Refresh = 0;
  if (HAL_OSPI_Init(&hospi1) != HAL_OK)
  {
    Error_Handler();
  }
  sOspiManagerCfg.ClkPort = 1;
  sOspiManagerCfg.NCSPort = 1;
  sOspiManagerCfg.IOLowPort = HAL_OSPIM_IOPORT_1_LOW;
  if (HAL_OSPIM_Config(&hospi1, &sOspiManagerCfg, HAL_OSPI_TIMEOUT_DEFAULT_VALUE) != HAL_OK)
  {
    Error_Handler();
  }

}

static void MX_SDMMC1_SD_Init(void)
{

  /* USER CODE BEGIN SDMMC1_Init 0 */
  if (BSP_SD_IsDetected() != SD_PRESENT)
  {
    // No card inserted; skip init so boot can continue.
    return;
  }
  /* USER CODE END SDMMC1_Init 0 */

  hsd1.Instance = SDMMC1;
  hsd1.Init.ClockEdge = SDMMC_CLOCK_EDGE_RISING;
  hsd1.Init.ClockPowerSave = SDMMC_CLOCK_POWER_SAVE_DISABLE;
  hsd1.Init.BusWide = SDMMC_BUS_WIDE_4B;
  hsd1.Init.HardwareFlowControl = SDMMC_HARDWARE_FLOW_CONTROL_DISABLE;
  hsd1.Init.ClockDiv = 1;
  if (HAL_SD_Init(&hsd1) != HAL_OK)
  {
    Error_Handler();
  }

}

static void MX_SPI1_Init(void)
{

  /* SPI1 parameter configuration*/
  hspi1.Instance = SPI1;
  hspi1.Init.Mode = SPI_MODE_MASTER;
  hspi1.Init.Direction = SPI_DIRECTION_2LINES;
  hspi1.Init.DataSize = SPI_DATASIZE_4BIT;
  hspi1.Init.CLKPolarity = SPI_POLARITY_LOW;
  hspi1.Init.CLKPhase = SPI_PHASE_1EDGE;
  hspi1.Init.NSS = SPI_NSS_SOFT;
  hspi1.Init.BaudRatePrescaler = SPI_BAUDRATEPRESCALER_8;
  hspi1.Init.FirstBit = SPI_FIRSTBIT_MSB;
  hspi1.Init.TIMode = SPI_TIMODE_DISABLE;
  hspi1.Init.CRCCalculation = SPI_CRCCALCULATION_DISABLE;
  hspi1.Init.CRCPolynomial = 0x0;
  hspi1.Init.NSSPMode = SPI_NSS_PULSE_ENABLE;
  hspi1.Init.NSSPolarity = SPI_NSS_POLARITY_LOW;
  hspi1.Init.FifoThreshold = SPI_FIFO_THRESHOLD_01DATA;
  hspi1.Init.TxCRCInitializationPattern = SPI_CRC_INITIALIZATION_ALL_ZERO_PATTERN;
  hspi1.Init.RxCRCInitializationPattern = SPI_CRC_INITIALIZATION_ALL_ZERO_PATTERN;
  hspi1.Init.MasterSSIdleness = SPI_MASTER_SS_IDLENESS_00CYCLE;
  hspi1.Init.MasterInterDataIdleness = SPI_MASTER_INTERDATA_IDLENESS_00CYCLE;
  hspi1.Init.MasterReceiverAutoSusp = SPI_MASTER_RX_AUTOSUSP_DISABLE;
  hspi1.Init.MasterKeepIOState = SPI_MASTER_KEEP_IO_STATE_DISABLE;
  hspi1.Init.IOSwap = SPI_IO_SWAP_DISABLE;
  if (HAL_SPI_Init(&hspi1) != HAL_OK)
  {
    Error_Handler();
  }

}

static void MX_SPI4_Init(void)
{

  /* SPI4 parameter configuration*/
  hspi4.Instance = SPI4;
  hspi4.Init.Mode = SPI_MODE_MASTER;
  hspi4.Init.Direction = SPI_DIRECTION_2LINES_TXONLY;
  hspi4.Init.DataSize = SPI_DATASIZE_4BIT;
  hspi4.Init.CLKPolarity = SPI_POLARITY_LOW;
  hspi4.Init.CLKPhase = SPI_PHASE_1EDGE;
  hspi4.Init.NSS = SPI_NSS_SOFT;
  hspi4.Init.BaudRatePrescaler = SPI_BAUDRATEPRESCALER_2;
  hspi4.Init.FirstBit = SPI_FIRSTBIT_MSB;
  hspi4.Init.TIMode = SPI_TIMODE_DISABLE;
  hspi4.Init.CRCCalculation = SPI_CRCCALCULATION_DISABLE;
  hspi4.Init.CRCPolynomial = 0x0;
  hspi4.Init.NSSPMode = SPI_NSS_PULSE_ENABLE;
  hspi4.Init.NSSPolarity = SPI_NSS_POLARITY_LOW;
  hspi4.Init.FifoThreshold = SPI_FIFO_THRESHOLD_01DATA;
  hspi4.Init.TxCRCInitializationPattern = SPI_CRC_INITIALIZATION_ALL_ZERO_PATTERN;
  hspi4.Init.RxCRCInitializationPattern = SPI_CRC_INITIALIZATION_ALL_ZERO_PATTERN;
  hspi4.Init.MasterSSIdleness = SPI_MASTER_SS_IDLENESS_00CYCLE;
  hspi4.Init.MasterInterDataIdleness = SPI_MASTER_INTERDATA_IDLENESS_00CYCLE;
  hspi4.Init.MasterReceiverAutoSusp = SPI_MASTER_RX_AUTOSUSP_DISABLE;
  hspi4.Init.MasterKeepIOState = SPI_MASTER_KEEP_IO_STATE_DISABLE;
  hspi4.Init.IOSwap = SPI_IO_SWAP_DISABLE;
  if (HAL_SPI_Init(&hspi4) != HAL_OK)
  {
    Error_Handler();
  }

}

static void MX_SPI6_Init(void)
{

  /* SPI6 parameter configuration*/
  hspi6.Instance = SPI6;
  hspi6.Init.Mode = SPI_MODE_MASTER;
  hspi6.Init.Direction = SPI_DIRECTION_2LINES;
  hspi6.Init.DataSize = SPI_DATASIZE_8BIT;
  hspi6.Init.CLKPolarity = SPI_POLARITY_LOW;
  hspi6.Init.CLKPhase = SPI_PHASE_1EDGE;
  hspi6.Init.NSS = SPI_NSS_SOFT;
  hspi6.Init.BaudRatePrescaler = SPI_BAUDRATEPRESCALER_8;
  hspi6.Init.FirstBit = SPI_FIRSTBIT_MSB;
  hspi6.Init.TIMode = SPI_TIMODE_DISABLE;
  hspi6.Init.CRCCalculation = SPI_CRCCALCULATION_DISABLE;
  hspi6.Init.CRCPolynomial = 0x0;
  hspi6.Init.NSSPMode = SPI_NSS_PULSE_ENABLE;
  hspi6.Init.NSSPolarity = SPI_NSS_POLARITY_LOW;
  hspi6.Init.FifoThreshold = SPI_FIFO_THRESHOLD_01DATA;
  hspi6.Init.TxCRCInitializationPattern = SPI_CRC_INITIALIZATION_ALL_ZERO_PATTERN;
  hspi6.Init.RxCRCInitializationPattern = SPI_CRC_INITIALIZATION_ALL_ZERO_PATTERN;
  hspi6.Init.MasterSSIdleness = SPI_MASTER_SS_IDLENESS_00CYCLE;
  hspi6.Init.MasterInterDataIdleness = SPI_MASTER_INTERDATA_IDLENESS_00CYCLE;
  hspi6.Init.MasterReceiverAutoSusp = SPI_MASTER_RX_AUTOSUSP_DISABLE;
  hspi6.Init.MasterKeepIOState = SPI_MASTER_KEEP_IO_STATE_DISABLE;
  hspi6.Init.IOSwap = SPI_IO_SWAP_DISABLE;
  if (HAL_SPI_Init(&hspi6) != HAL_OK)
  {
    Error_Handler();
  }

}

static void MX_TIM1_Init(void)
{

  TIM_MasterConfigTypeDef sMasterConfig = {0};
  TIM_OC_InitTypeDef sConfigOC = {0};
  TIM_BreakDeadTimeConfigTypeDef sBreakDeadTimeConfig = {0};

  htim1.Instance = TIM1;
  htim1.Init.Prescaler = 199;
  htim1.Init.CounterMode = TIM_COUNTERMODE_UP;
  htim1.Init.Period = 44;
  htim1.Init.ClockDivision = TIM_CLOCKDIVISION_DIV1;
  htim1.Init.RepetitionCounter = 0;
  htim1.Init.AutoReloadPreload = TIM_AUTORELOAD_PRELOAD_ENABLE;
  if (HAL_TIM_PWM_Init(&htim1) != HAL_OK)
  {
    Error_Handler();
  }
  sMasterConfig.MasterOutputTrigger = TIM_TRGO_RESET;
  sMasterConfig.MasterOutputTrigger2 = TIM_TRGO2_RESET;
  sMasterConfig.MasterSlaveMode = TIM_MASTERSLAVEMODE_DISABLE;
  if (HAL_TIMEx_MasterConfigSynchronization(&htim1, &sMasterConfig) != HAL_OK)
  {
    Error_Handler();
  }
  sConfigOC.OCMode = TIM_OCMODE_PWM1;
  sConfigOC.Pulse = 0;
  sConfigOC.OCPolarity = TIM_OCPOLARITY_HIGH;
  sConfigOC.OCNPolarity = TIM_OCNPOLARITY_HIGH;
  sConfigOC.OCFastMode = TIM_OCFAST_DISABLE;
  sConfigOC.OCIdleState = TIM_OCIDLESTATE_RESET;
  sConfigOC.OCNIdleState = TIM_OCNIDLESTATE_RESET;
  if (HAL_TIM_PWM_ConfigChannel(&htim1, &sConfigOC, TIM_CHANNEL_2) != HAL_OK)
  {
    Error_Handler();
  }
  sBreakDeadTimeConfig.OffStateRunMode = TIM_OSSR_DISABLE;
  sBreakDeadTimeConfig.OffStateIDLEMode = TIM_OSSI_DISABLE;
  sBreakDeadTimeConfig.LockLevel = TIM_LOCKLEVEL_OFF;
  sBreakDeadTimeConfig.DeadTime = 0;
  sBreakDeadTimeConfig.BreakState = TIM_BREAK_DISABLE;
  sBreakDeadTimeConfig.BreakPolarity = TIM_BREAKPOLARITY_HIGH;
  sBreakDeadTimeConfig.BreakFilter = 0;
  sBreakDeadTimeConfig.Break2State = TIM_BREAK2_DISABLE;
  sBreakDeadTimeConfig.Break2Polarity = TIM_BREAK2POLARITY_HIGH;
  sBreakDeadTimeConfig.Break2Filter = 0;
  sBreakDeadTimeConfig.AutomaticOutput = TIM_AUTOMATICOUTPUT_DISABLE;
  if (HAL_TIMEx_ConfigBreakDeadTime(&htim1, &sBreakDeadTimeConfig) != HAL_OK)
  {
    Error_Handler();
  }
  HAL_TIM_MspPostInit(&htim1);

}

static void MX_TIM2_Init(void)
{

  TIM_ClockConfigTypeDef sClockSourceConfig = {0};
  TIM_MasterConfigTypeDef sMasterConfig = {0};

  htim2.Instance = TIM2;
  htim2.Init.Prescaler = 499;
  htim2.Init.CounterMode = TIM_COUNTERMODE_UP;
  htim2.Init.Period = 999;
  htim2.Init.ClockDivision = TIM_CLOCKDIVISION_DIV1;
  htim2.Init.AutoReloadPreload = TIM_AUTORELOAD_PRELOAD_ENABLE;
  if (HAL_TIM_Base_Init(&htim2) != HAL_OK)
  {
    Error_Handler();
  }
  sClockSourceConfig.ClockSource = TIM_CLOCKSOURCE_INTERNAL;
  if (HAL_TIM_ConfigClockSource(&htim2, &sClockSourceConfig) != HAL_OK)
  {
    Error_Handler();
  }
  sMasterConfig.MasterOutputTrigger = TIM_TRGO_RESET;
  sMasterConfig.MasterSlaveMode = TIM_MASTERSLAVEMODE_DISABLE;
  if (HAL_TIMEx_MasterConfigSynchronization(&htim2, &sMasterConfig) != HAL_OK)
  {
    Error_Handler();
  }

}

static void MX_UART5_Init(void)
{

  huart5.Instance = UART5;
  huart5.Init.BaudRate = 115200;
  huart5.Init.WordLength = UART_WORDLENGTH_8B;
  huart5.Init.StopBits = UART_STOPBITS_1;
  huart5.Init.Parity = UART_PARITY_NONE;
  huart5.Init.Mode = UART_MODE_TX_RX;
  huart5.Init.HwFlowCtl = UART_HWCONTROL_NONE;
  huart5.Init.OverSampling = UART_OVERSAMPLING_16;
  huart5.Init.OneBitSampling = UART_ONE_BIT_SAMPLE_DISABLE;
  huart5.Init.ClockPrescaler = UART_PRESCALER_DIV1;
  huart5.AdvancedInit.AdvFeatureInit = UART_ADVFEATURE_NO_INIT;
  if (HAL_UART_Init(&huart5) != HAL_OK)
  {
    Error_Handler();
  }
  if (HAL_UARTEx_SetTxFifoThreshold(&huart5, UART_TXFIFO_THRESHOLD_1_8) != HAL_OK)
  {
    Error_Handler();
  }
  if (HAL_UARTEx_SetRxFifoThreshold(&huart5, UART_RXFIFO_THRESHOLD_1_8) != HAL_OK)
  {
    Error_Handler();
  }
  if (HAL_UARTEx_DisableFifoMode(&huart5) != HAL_OK)
  {
    Error_Handler();
  }

}

static void MX_UART7_Init(void)
{

  huart7.Instance = UART7;
  huart7.Init.BaudRate = 115200;
  huart7.Init.WordLength = UART_WORDLENGTH_8B;
  huart7.Init.StopBits = UART_STOPBITS_1;
  huart7.Init.Parity = UART_PARITY_NONE;
  huart7.Init.Mode = UART_MODE_TX_RX;
  huart7.Init.HwFlowCtl = UART_HWCONTROL_NONE;
  huart7.Init.OverSampling = UART_OVERSAMPLING_16;
  huart7.Init.OneBitSampling = UART_ONE_BIT_SAMPLE_DISABLE;
  huart7.Init.ClockPrescaler = UART_PRESCALER_DIV1;
  huart7.AdvancedInit.AdvFeatureInit = UART_ADVFEATURE_NO_INIT;
  if (HAL_UART_Init(&huart7) != HAL_OK)
  {
    Error_Handler();
  }
  if (HAL_UARTEx_SetTxFifoThreshold(&huart7, UART_TXFIFO_THRESHOLD_1_8) != HAL_OK)
  {
    Error_Handler();
  }
  if (HAL_UARTEx_SetRxFifoThreshold(&huart7, UART_RXFIFO_THRESHOLD_1_8) != HAL_OK)
  {
    Error_Handler();
  }
  if (HAL_UARTEx_DisableFifoMode(&huart7) != HAL_OK)
  {
    Error_Handler();
  }

}

static void MX_UART8_Init(void)
{

  huart8.Instance = UART8;
  huart8.Init.BaudRate = 115200;
  huart8.Init.WordLength = UART_WORDLENGTH_8B;
  huart8.Init.StopBits = UART_STOPBITS_1;
  huart8.Init.Parity = UART_PARITY_NONE;
  huart8.Init.Mode = UART_MODE_TX_RX;
  huart8.Init.HwFlowCtl = UART_HWCONTROL_NONE;
  huart8.Init.OverSampling = UART_OVERSAMPLING_16;
  huart8.Init.OneBitSampling = UART_ONE_BIT_SAMPLE_DISABLE;
  huart8.Init.ClockPrescaler = UART_PRESCALER_DIV1;
  huart8.AdvancedInit.AdvFeatureInit = UART_ADVFEATURE_NO_INIT;
  if (HAL_UART_Init(&huart8) != HAL_OK)
  {
    Error_Handler();
  }
  if (HAL_UARTEx_SetTxFifoThreshold(&huart8, UART_TXFIFO_THRESHOLD_1_8) != HAL_OK)
  {
    Error_Handler();
  }
  if (HAL_UARTEx_SetRxFifoThreshold(&huart8, UART_RXFIFO_THRESHOLD_1_8) != HAL_OK)
  {
    Error_Handler();
  }
  if (HAL_UARTEx_DisableFifoMode(&huart8) != HAL_OK)
  {
    Error_Handler();
  }

}

static void MX_USART1_UART_Init(void)
{

  huart1.Instance = USART1;
  huart1.Init.BaudRate = 460800;
  huart1.Init.WordLength = UART_WORDLENGTH_8B;
  huart1.Init.StopBits = UART_STOPBITS_1;
  huart1.Init.Parity = UART_PARITY_NONE;
  huart1.Init.Mode = UART_MODE_TX_RX;
  huart1.Init.HwFlowCtl = UART_HWCONTROL_NONE;
  huart1.Init.OverSampling = UART_OVERSAMPLING_16;
  huart1.Init.OneBitSampling = UART_ONE_BIT_SAMPLE_DISABLE;
  huart1.Init.ClockPrescaler = UART_PRESCALER_DIV1;
  huart1.AdvancedInit.AdvFeatureInit = UART_ADVFEATURE_NO_INIT;
  if (HAL_UART_Init(&huart1) != HAL_OK)
  {
    Error_Handler();
  }
  if (HAL_UARTEx_SetTxFifoThreshold(&huart1, UART_TXFIFO_THRESHOLD_1_8) != HAL_OK)
  {
    Error_Handler();
  }
  if (HAL_UARTEx_SetRxFifoThreshold(&huart1, UART_RXFIFO_THRESHOLD_1_8) != HAL_OK)
  {
    Error_Handler();
  }
  if (HAL_UARTEx_DisableFifoMode(&huart1) != HAL_OK)
  {
    Error_Handler();
  }

}

static void MX_USART2_UART_Init(void)
{

  huart2.Instance = USART2;
  huart2.Init.BaudRate = 921600;
  huart2.Init.WordLength = UART_WORDLENGTH_8B;
  huart2.Init.StopBits = UART_STOPBITS_1;
  huart2.Init.Parity = UART_PARITY_NONE;
  huart2.Init.Mode = UART_MODE_TX_RX;
  huart2.Init.HwFlowCtl = UART_HWCONTROL_RTS_CTS;
  huart2.Init.OverSampling = UART_OVERSAMPLING_16;
  huart2.Init.OneBitSampling = UART_ONE_BIT_SAMPLE_DISABLE;
  huart2.Init.ClockPrescaler = UART_PRESCALER_DIV1;
  huart2.AdvancedInit.AdvFeatureInit = UART_ADVFEATURE_NO_INIT;
  if (HAL_UART_Init(&huart2) != HAL_OK)
  {
    Error_Handler();
  }
  if (HAL_UARTEx_SetTxFifoThreshold(&huart2, UART_TXFIFO_THRESHOLD_1_8) != HAL_OK)
  {
    Error_Handler();
  }
  if (HAL_UARTEx_SetRxFifoThreshold(&huart2, UART_RXFIFO_THRESHOLD_1_8) != HAL_OK)
  {
    Error_Handler();
  }
  if (HAL_UARTEx_DisableFifoMode(&huart2) != HAL_OK)
  {
    Error_Handler();
  }

}

static void MX_USART3_UART_Init(void)
{

  huart3.Instance = USART3;
  huart3.Init.BaudRate = 115200;
  huart3.Init.WordLength = UART_WORDLENGTH_8B;
  huart3.Init.StopBits = UART_STOPBITS_1;
  huart3.Init.Parity = UART_PARITY_NONE;
  huart3.Init.Mode = UART_MODE_TX_RX;
  huart3.Init.HwFlowCtl = UART_HWCONTROL_NONE;
  huart3.Init.OverSampling = UART_OVERSAMPLING_16;
  huart3.Init.OneBitSampling = UART_ONE_BIT_SAMPLE_DISABLE;
  huart3.Init.ClockPrescaler = UART_PRESCALER_DIV1;
  huart3.AdvancedInit.AdvFeatureInit = UART_ADVFEATURE_NO_INIT;
  if (HAL_UART_Init(&huart3) != HAL_OK)
  {
    Error_Handler();
  }
  if (HAL_UARTEx_SetTxFifoThreshold(&huart3, UART_TXFIFO_THRESHOLD_1_8) != HAL_OK)
  {
    Error_Handler();
  }
  if (HAL_UARTEx_SetRxFifoThreshold(&huart3, UART_RXFIFO_THRESHOLD_1_8) != HAL_OK)
  {
    Error_Handler();
  }
  if (HAL_UARTEx_DisableFifoMode(&huart3) != HAL_OK)
  {
    Error_Handler();
  }

}

static void MX_USART6_UART_Init(void)
{

  huart6.Instance = USART6;
  huart6.Init.BaudRate = 460800;
  huart6.Init.WordLength = UART_WORDLENGTH_8B;
  huart6.Init.StopBits = UART_STOPBITS_1;
  huart6.Init.Parity = UART_PARITY_NONE;
  huart6.Init.Mode = UART_MODE_TX_RX;
  huart6.Init.HwFlowCtl = UART_HWCONTROL_NONE;
  huart6.Init.OverSampling = UART_OVERSAMPLING_16;
  huart6.Init.OneBitSampling = UART_ONE_BIT_SAMPLE_DISABLE;
  huart6.Init.ClockPrescaler = UART_PRESCALER_DIV1;
  huart6.AdvancedInit.AdvFeatureInit = UART_ADVFEATURE_NO_INIT;
  if (HAL_UART_Init(&huart6) != HAL_OK)
  {
    Error_Handler();
  }
  if (HAL_UARTEx_SetTxFifoThreshold(&huart6, UART_TXFIFO_THRESHOLD_1_8) != HAL_OK)
  {
    Error_Handler();
  }
  if (HAL_UARTEx_SetRxFifoThreshold(&huart6, UART_RXFIFO_THRESHOLD_1_8) != HAL_OK)
  {
    Error_Handler();
  }
  if (HAL_UARTEx_DisableFifoMode(&huart6) != HAL_OK)
  {
    Error_Handler();
  }

}

static void MX_BDMA_Init(void)
{

  /* DMA controller clock enable */
  __HAL_RCC_BDMA_CLK_ENABLE();

  /* DMA interrupt init */
  /* BDMA_Channel0_IRQn interrupt configuration */
  HAL_NVIC_SetPriority(BDMA_Channel0_IRQn, 0, 0);
  HAL_NVIC_EnableIRQ(BDMA_Channel0_IRQn);
  /* BDMA_Channel1_IRQn interrupt configuration */
  HAL_NVIC_SetPriority(BDMA_Channel1_IRQn, 0, 0);
  HAL_NVIC_EnableIRQ(BDMA_Channel1_IRQn);

}

static void MX_DMA_Init(void)
{

  /* DMA controller clock enable */
  __HAL_RCC_DMA1_CLK_ENABLE();
  __HAL_RCC_DMA2_CLK_ENABLE();

  /* DMA interrupt init */
  /* DMA1_Stream4_IRQn interrupt configuration */
  HAL_NVIC_SetPriority(DMA1_Stream4_IRQn, 0, 0);
  HAL_NVIC_EnableIRQ(DMA1_Stream4_IRQn);
  /* DMA1_Stream5_IRQn interrupt configuration */
  HAL_NVIC_SetPriority(DMA1_Stream5_IRQn, 0, 0);
  HAL_NVIC_EnableIRQ(DMA1_Stream5_IRQn);
  /* DMA1_Stream6_IRQn interrupt configuration */
  HAL_NVIC_SetPriority(DMA1_Stream6_IRQn, 0, 0);
  HAL_NVIC_EnableIRQ(DMA1_Stream6_IRQn);
  /* DMA1_Stream7_IRQn interrupt configuration */
  HAL_NVIC_SetPriority(DMA1_Stream7_IRQn, 0, 0);
  HAL_NVIC_EnableIRQ(DMA1_Stream7_IRQn);
  /* DMA2_Stream0_IRQn interrupt configuration */
  HAL_NVIC_SetPriority(DMA2_Stream0_IRQn, 0, 0);
  HAL_NVIC_EnableIRQ(DMA2_Stream0_IRQn);
  /* DMA2_Stream1_IRQn interrupt configuration */
  HAL_NVIC_SetPriority(DMA2_Stream1_IRQn, 0, 0);
  HAL_NVIC_EnableIRQ(DMA2_Stream1_IRQn);
  /* DMA2_Stream2_IRQn interrupt configuration */
  HAL_NVIC_SetPriority(DMA2_Stream2_IRQn, 0, 0);
  HAL_NVIC_EnableIRQ(DMA2_Stream2_IRQn);
  /* DMA2_Stream3_IRQn interrupt configuration */
  HAL_NVIC_SetPriority(DMA2_Stream3_IRQn, 0, 0);
  HAL_NVIC_EnableIRQ(DMA2_Stream3_IRQn);
  /* DMA2_Stream4_IRQn interrupt configuration */
  HAL_NVIC_SetPriority(DMA2_Stream4_IRQn, 0, 0);
  HAL_NVIC_EnableIRQ(DMA2_Stream4_IRQn);
  /* DMA2_Stream5_IRQn interrupt configuration */
  HAL_NVIC_SetPriority(DMA2_Stream5_IRQn, 0, 0);
  HAL_NVIC_EnableIRQ(DMA2_Stream5_IRQn);

}

/**
  * Enable MDMA controller clock
  */
static void MX_MDMA_Init(void)
{

  /* MDMA controller clock enable */
  __HAL_RCC_MDMA_CLK_ENABLE();
  /* Local variables */

  /* MDMA interrupt initialization */
  /* MDMA_IRQn interrupt configuration */
  HAL_NVIC_SetPriority(MDMA_IRQn, 0, 0);
  HAL_NVIC_EnableIRQ(MDMA_IRQn);

}

static void MX_GPIO_Init(void)
{
  GPIO_InitTypeDef GPIO_InitStruct = {0};

  /* GPIO Ports Clock Enable */
  __HAL_RCC_GPIOE_CLK_ENABLE();
  __HAL_RCC_GPIOC_CLK_ENABLE();
  __HAL_RCC_GPIOH_CLK_ENABLE();
  __HAL_RCC_GPIOA_CLK_ENABLE();
  __HAL_RCC_GPIOB_CLK_ENABLE();
  __HAL_RCC_GPIOD_CLK_ENABLE();

  /*Configure GPIO pin Output Level */
  HAL_GPIO_WritePin(GPIOE, BL_LED_Pin|LCD_CS_Pin|LVCD_WS_RS_Pin, GPIO_PIN_RESET);

  /*Configure GPIO pin Output Level */
  HAL_GPIO_WritePin(GPIOB, LED_RED_Pin|LED_GREEN_Pin, GPIO_PIN_RESET);

  /*Configure GPIO pin Output Level */
  HAL_GPIO_WritePin(GPIOD, BMM150_CS_Pin|BMI270_CS_Pin|ICM42688_CS_Pin|SPI_FLASH_CS_Pin, GPIO_PIN_SET);

  /*Configure GPIO pin : BL_LED_Pin */
  GPIO_InitStruct.Pin = BL_LED_Pin;
  GPIO_InitStruct.Mode = GPIO_MODE_OUTPUT_PP;
  GPIO_InitStruct.Pull = GPIO_NOPULL;
  GPIO_InitStruct.Speed = GPIO_SPEED_FREQ_LOW;
  HAL_GPIO_Init(BL_LED_GPIO_Port, &GPIO_InitStruct);

  /*Configure GPIO pins : BTN2_Pin BTN3_Pin BTN5_Pin */
  GPIO_InitStruct.Pin = BTN2_Pin|BTN3_Pin|BTN5_Pin;
  GPIO_InitStruct.Mode = GPIO_MODE_INPUT;
  GPIO_InitStruct.Pull = GPIO_PULLUP;
  HAL_GPIO_Init(GPIOE, &GPIO_InitStruct);

  /*Configure GPIO pin : SW2_Pin */
  GPIO_InitStruct.Pin = SW2_Pin;
  GPIO_InitStruct.Mode = GPIO_MODE_INPUT;
  GPIO_InitStruct.Pull = GPIO_NOPULL;
  HAL_GPIO_Init(SW2_GPIO_Port, &GPIO_InitStruct);

  /*Configure GPIO pins : ICM42688_INT1_Pin BMI270_INT1_Pin BMM150_INT1_Pin */
  GPIO_InitStruct.Pin = ICM42688_INT1_Pin|BMI270_INT1_Pin|BMM150_INT1_Pin;
  GPIO_InitStruct.Mode = GPIO_MODE_IT_RISING;
  GPIO_InitStruct.Pull = GPIO_NOPULL;
  HAL_GPIO_Init(GPIOC, &GPIO_InitStruct);

  /*Configure GPIO pin : BTN1_Pin */
  GPIO_InitStruct.Pin = BTN1_Pin;
  GPIO_InitStruct.Mode = GPIO_MODE_INPUT;
  GPIO_InitStruct.Pull = GPIO_NOPULL;
  HAL_GPIO_Init(BTN1_GPIO_Port, &GPIO_InitStruct);

  /*Configure GPIO pins : LED_RED_Pin LED_GREEN_Pin */
  GPIO_InitStruct.Pin = LED_RED_Pin|LED_GREEN_Pin;
  GPIO_InitStruct.Mode = GPIO_MODE_OUTPUT_PP;
  GPIO_InitStruct.Pull = GPIO_NOPULL;
  GPIO_InitStruct.Speed = GPIO_SPEED_FREQ_LOW;
  HAL_GPIO_Init(GPIOB, &GPIO_InitStruct);

  /*Configure GPIO pins : LCD_CS_Pin LVCD_WS_RS_Pin */
  GPIO_InitStruct.Pin = LCD_CS_Pin|LVCD_WS_RS_Pin;
  GPIO_InitStruct.Mode = GPIO_MODE_OUTPUT_PP;
  GPIO_InitStruct.Pull = GPIO_NOPULL;
  GPIO_InitStruct.Speed = GPIO_SPEED_FREQ_HIGH;
  HAL_GPIO_Init(GPIOE, &GPIO_InitStruct);

  /*Configure GPIO pins : BMM150_CS_Pin BMI270_CS_Pin ICM42688_CS_Pin SPI_FLASH_CS_Pin */
  GPIO_InitStruct.Pin = BMM150_CS_Pin|BMI270_CS_Pin|ICM42688_CS_Pin|SPI_FLASH_CS_Pin;
  GPIO_InitStruct.Mode = GPIO_MODE_OUTPUT_PP;
  GPIO_InitStruct.Pull = GPIO_NOPULL;
  GPIO_InitStruct.Speed = GPIO_SPEED_FREQ_VERY_HIGH;
  HAL_GPIO_Init(GPIOD, &GPIO_InitStruct);

  /*Configure GPIO pins : LeftHipUpperLimit_Pin LeftHipLowerLimit_Pin */
  GPIO_InitStruct.Pin = LeftHipUpperLimit_Pin|LeftHipLowerLimit_Pin;
  GPIO_InitStruct.Mode = GPIO_MODE_INPUT;
  GPIO_InitStruct.Pull = GPIO_PULLUP;
  HAL_GPIO_Init(GPIOA, &GPIO_InitStruct);

  /*Configure GPIO pins : RightHipUpperLimit_Pin MICROSD_SW_Pin RightHipLowerLimit_Pin */
  GPIO_InitStruct.Pin = RightHipUpperLimit_Pin|MICROSD_SW_Pin|RightHipLowerLimit_Pin;
  GPIO_InitStruct.Mode = GPIO_MODE_INPUT;
  GPIO_InitStruct.Pull = GPIO_PULLUP;
  HAL_GPIO_Init(GPIOD, &GPIO_InitStruct);

  /* EXTI interrupt init*/
  HAL_NVIC_SetPriority(ICM42688_INT1_EXTI_IRQn, 0, 0);
  HAL_NVIC_EnableIRQ(ICM42688_INT1_EXTI_IRQn);

  HAL_NVIC_SetPriority(BMI270_INT1_EXTI_IRQn, 0, 0);
  HAL_NVIC_EnableIRQ(BMI270_INT1_EXTI_IRQn);

  HAL_NVIC_SetPriority(BMM150_INT1_EXTI_IRQn, 0, 0);
  HAL_NVIC_EnableIRQ(BMM150_INT1_EXTI_IRQn);

  /* USER CODE BEGIN MX_GPIO_Init_2 */
  GPIO_InitStruct.Pin = BMI270_INT1_Pin;
  GPIO_InitStruct.Mode = GPIO_MODE_IT_FALLING;
  GPIO_InitStruct.Pull = GPIO_NOPULL;
  HAL_GPIO_Init(BMI270_INT1_GPIO_Port, &GPIO_InitStruct);

  /* USER CODE END MX_GPIO_Init_2 */
}

 /* MPU Configuration */

void MPU_Config(void)
{
  MPU_Region_InitTypeDef MPU_InitStruct = {0};

  /* Disables the MPU */
  HAL_MPU_Disable();

  /** Initializes and configures the Region and the memory to be protected
  */
  MPU_InitStruct.Enable = MPU_REGION_ENABLE;
  MPU_InitStruct.Number = MPU_REGION_NUMBER0;
  MPU_InitStruct.BaseAddress = 0x0;
  MPU_InitStruct.Size = MPU_REGION_SIZE_4GB;
  MPU_InitStruct.SubRegionDisable = 0x87;
  MPU_InitStruct.TypeExtField = MPU_TEX_LEVEL0;
  MPU_InitStruct.AccessPermission = MPU_REGION_NO_ACCESS;
  MPU_InitStruct.DisableExec = MPU_INSTRUCTION_ACCESS_DISABLE;
  MPU_InitStruct.IsShareable = MPU_ACCESS_SHAREABLE;
  MPU_InitStruct.IsCacheable = MPU_ACCESS_NOT_CACHEABLE;
  MPU_InitStruct.IsBufferable = MPU_ACCESS_NOT_BUFFERABLE;

  HAL_MPU_ConfigRegion(&MPU_InitStruct);
  /* Enables the MPU */
  HAL_MPU_Enable(MPU_PRIVILEGED_DEFAULT);

}

void Error_Handler(void)
{
  /* USER CODE BEGIN Error_Handler_Debug */
  /* User can add his own implementation to report the HAL error return state */
  debug_wdog_checkpoint(WDOG_CP_ERROR_HANDLER, __LINE__);
  app_log_printf("Error_Handler invoked\r\n");
  app_log_flush_blocking(50U);
  system_reboot();
  while (1) {
  }
  /* USER CODE END Error_Handler_Debug */
}
#ifdef USE_FULL_ASSERT
/**
  * @brief  Reports the name of the source file and the source line number
  *         where the assert_param error has occurred.
  * @param  file: pointer to the source file name
  * @param  line: assert_param error line source number
  * @retval None
  */
void assert_failed(uint8_t *file, uint32_t line)
{
  /* USER CODE BEGIN 6 */
  /* User can add his own implementation to report the file name and line
     number, ex: printf("Wrong parameters value: file %s on line %d\r\n", file,
     line) */
  /* USER CODE END 6 */
}
#endif /* USE_FULL_ASSERT */
